# STM32WBA25 register map
File version: 1.0
CPU: CM33 r0p1, little endian, MPU, FPU, 4 interrupt priority bits
Registers are 32-bit, read-write, reset 0x0 unless marked. A register's access mark holds for its fields unless they carry their own. Offsets are from the block's base; [hi:lo] are bit positions; {n}, {i} and the like mark numbered series.

## HASH — HASH address block description
Base 0x420C0400
Same registers: SEC_HASH 0x520C0400
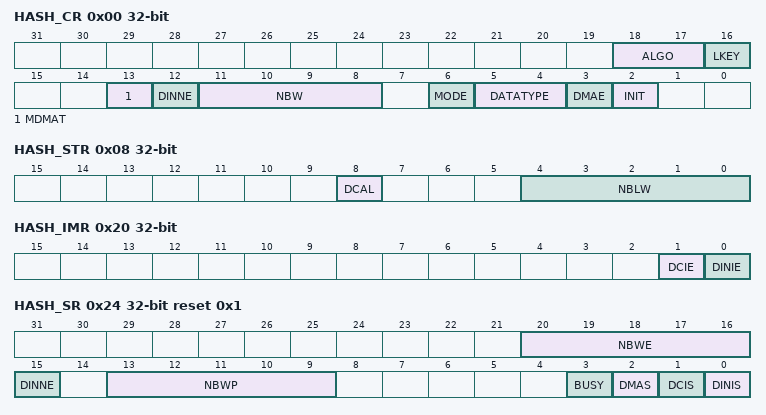
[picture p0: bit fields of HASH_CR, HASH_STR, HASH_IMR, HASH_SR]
0x00 HASH_CR — HASH control register
  [18:17] ALGO — Algorithm selection
    0=SHA-1; 2=SHA2-224; 3=SHA2-256
  [16] LKEY — Long key selection
    0=the HMAC key is shorter or equal to 64 bytes; 1=the HMAC key is longer than 64 bytes
  [13] MDMAT — Multiple DMA transfers
    0=DCAL is automatically set at the end of a DMA transfer; 1=DCAL is not automatically set at the end of a DMA transfer
  [12] DINNE ro — DIN not empty
  [11:8] NBW ro — Number of words already pushed
  [6] MODE — Mode selection
    0=Hash mode selected; 1=HMAC mode selected
  [5:4] DATATYPE — Data type selection
    0=32-bit data; 1=16-bit data, or half-word; 2=8-bit data, or bytes; 3=bit data, or bit-string
  [3] DMAE — DMA enable
    0=DMA transfers disabled; 1=DMA transfers enabled
  [2] INIT — Initialize message digest calculation
0x04 HASH_DIN wo — HASH data input register
  [31:0] DATAIN — Data input
0x08 HASH_STR — HASH start register
  [8] DCAL — Digest calculation
  [4:0] NBLW — Number of valid bits in the last word
    0=All 32 bits of the last data written are valid message bits that is M[31:0]; 1=Only one bit of the last data written (after swapping) is valid that is M[0]; 2=Only two bits of the last data written (after swapping) are valid that is M[1:0]; 3=Only three bits of the last data written (after swapping) are valid that is M[2:0]; 31=Only 31 bits of the last data written (after swapping) are valid that is M[30:0]
{0xC+4i} HASH_HRA{i} ro (i=0..4) — HASH aliased digest register {i}
  [31:0] H{i} — Hash data x
0x20 HASH_IMR — HASH interrupt enable register
  [1] DCIE — Digest calculation completion interrupt enable
    0=Digest calculation completion interrupt disabled; 1=Digest calculation completion interrupt enabled
  [0] DINIE — Data input interrupt enable
    0=Data input interrupt disabled; 1=Data input interrupt enabled
0x24 HASH_SR reset 0x1 — HASH status register
  [20:16] NBWE ro — Number of words expected
  [15] DINNE ro — DIN not empty
    0=No data are present in the data input buffer; 1=The input buffer contains at least one word of data
  [13:9] NBWP ro — Number of words already pushed
  [3] BUSY ro — Busy bit
    0=No block is currently being processed; 1=The hash core is processing a block of data
  [2] DMAS ro — DMA Status
    0=DMA interface is disabled (DMAE=0) and no transfer is ongoing; 1=DMA interface is enabled (DMAE=1) or a transfer is ongoing
  [1] DCIS — Digest calculation completion interrupt status
    0=No digest available in the HASH_HRx registers (zeros are returned); 1=Digest calculation complete, a digest is available in the HASH_HRx registers
  [0] DINIS — Data input interrupt status
    0=Less than 16 locations are free in the input buffer; 1=A new block can be entered into the input buffer
{0xF8+4i} HASH_CSR{i} (i=0..53) — HASH context swap register {i}
  [31:0] CS{i} — Context swap x
{0x310+4i} HASH_HR{i} ro (i=0..4) — HASH digest register {i}
  [31:0] H{i} — Hash data x
{0x310+4i} HASH_HR{i} ro (i=5..7) — HASH supplementary digest register {i}
  [31:0] H{i} — Hash data x

## IWDG — IWDG address block description
Base 0x40003000
Same registers: SEC_IWDG 0x50003000
0x00 IWDG_KR wo — IWDG key register
  [15:0] KEY — Key value (write only, read 0x0000)
0x04 IWDG_PR — IWDG prescaler register
  [3:0] PR — Prescaler divider
    0=divider / 4; 1=divider / 8; 2=divider / 16; 3=divider / 32; 4=divider / 64; 5=divider / 128; 6=divider / 256; 7=divider / 512
0x08 IWDG_RLR reset 0xFFF — IWDG reload register
  [11:0] RL — Watchdog counter reload value
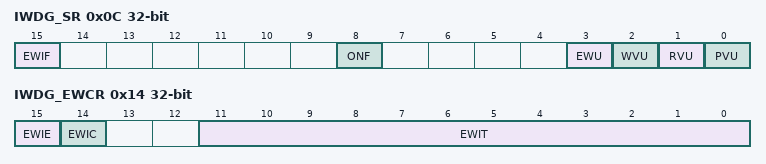
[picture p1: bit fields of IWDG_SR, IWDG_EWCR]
0x0C IWDG_SR ro — IWDG status register
  [15] EWIF — Watchdog early interrupt flag
  [8] ONF — Watchdog enable status bit
    0=The IWDG is not activated; 1=The IWDG is activated and needs to be refreshed regularly by the application
  [3] EWU — Watchdog interrupt comparator value update
  [2] WVU — Watchdog counter window value update
  [1] RVU — Watchdog counter reload value update
  [0] PVU — Watchdog prescaler value update
0x10 IWDG_WINR reset 0xFFF — IWDG window register
  [11:0] WIN — Watchdog counter window value
0x14 IWDG_EWCR — IWDG early wakeup interrupt register
  [15] EWIE — Watchdog early interrupt enable
    0=The early interrupt interface is disabled; 1=The early interrupt interface is enabled
  [14] EWIC wo — Watchdog early interrupt acknowledge
  [11:0] EWIT — Watchdog counter window value
